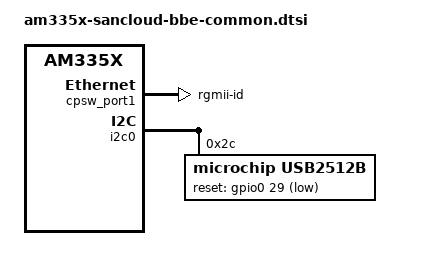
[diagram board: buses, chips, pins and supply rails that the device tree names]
// SPDX-License-Identifier: GPL-2.0-only
/*
 * Copyright (C) 2012 Texas Instruments Incorporated - https://www.ti.com/
 */

&am33xx_pinmux {
	cpsw_default: cpsw-default-pins {
		pinctrl-single,pins = <
			/* Slave 1 */
			AM33XX_PADCONF(AM335X_PIN_MII1_TX_EN, PIN_OUTPUT_PULLDOWN, MUX_MODE2)	/* mii1_txen.rgmii1_tctl */
			AM33XX_PADCONF(AM335X_PIN_MII1_RX_DV, PIN_INPUT_PULLDOWN, MUX_MODE2)	/* mii1_rxdv.rgmii1_rctl */
			AM33XX_PADCONF(AM335X_PIN_MII1_TXD3, PIN_OUTPUT_PULLDOWN, MUX_MODE2)	/* mii1_txd3.rgmii1_td3 */
			AM33XX_PADCONF(AM335X_PIN_MII1_TXD2, PIN_OUTPUT_PULLDOWN, MUX_MODE2)	/* mii1_txd2.rgmii1_td2 */
			AM33XX_PADCONF(AM335X_PIN_MII1_TXD1, PIN_OUTPUT_PULLDOWN, MUX_MODE2)	/* mii1_txd1.rgmii1_td1 */
			AM33XX_PADCONF(AM335X_PIN_MII1_TXD0, PIN_OUTPUT_PULLDOWN, MUX_MODE2)	/* mii1_txd0.rgmii1_td0 */
			AM33XX_PADCONF(AM335X_PIN_MII1_TX_CLK, PIN_OUTPUT_PULLDOWN, MUX_MODE2)	/* mii1_txclk.rgmii1_tclk */
			AM33XX_PADCONF(AM335X_PIN_MII1_RX_CLK, PIN_INPUT_PULLDOWN, MUX_MODE2)	/* mii1_rxclk.rgmii1_rclk */
			AM33XX_PADCONF(AM335X_PIN_MII1_RXD3, PIN_INPUT_PULLDOWN, MUX_MODE2)	/* mii1_rxd3.rgmii1_rd3 */
			AM33XX_PADCONF(AM335X_PIN_MII1_RXD2, PIN_INPUT_PULLDOWN, MUX_MODE2)	/* mii1_rxd2.rgmii1_rd2 */
			AM33XX_PADCONF(AM335X_PIN_MII1_RXD1, PIN_INPUT_PULLDOWN, MUX_MODE2)	/* mii1_rxd1.rgmii1_rd1 */
			AM33XX_PADCONF(AM335X_PIN_MII1_RXD0, PIN_INPUT_PULLDOWN, MUX_MODE2)	/* mii1_rxd0.rgmii1_rd0 */
		>;
	};

	cpsw_sleep: cpsw-sleep-pins {
		pinctrl-single,pins = <
			/* Slave 1 reset value */
			AM33XX_PADCONF(AM335X_PIN_MII1_TX_EN, PIN_INPUT_PULLDOWN, MUX_MODE7)
			AM33XX_PADCONF(AM335X_PIN_MII1_RX_DV, PIN_INPUT_PULLDOWN, MUX_MODE7)
			AM33XX_PADCONF(AM335X_PIN_MII1_TXD3, PIN_INPUT_PULLDOWN, MUX_MODE7)
			AM33XX_PADCONF(AM335X_PIN_MII1_TXD2, PIN_INPUT_PULLDOWN, MUX_MODE7)
			AM33XX_PADCONF(AM335X_PIN_MII1_TXD1, PIN_INPUT_PULLDOWN, MUX_MODE7)
			AM33XX_PADCONF(AM335X_PIN_MII1_TXD0, PIN_INPUT_PULLDOWN, MUX_MODE7)
			AM33XX_PADCONF(AM335X_PIN_MII1_TX_CLK, PIN_INPUT_PULLDOWN, MUX_MODE7)
			AM33XX_PADCONF(AM335X_PIN_MII1_RX_CLK, PIN_INPUT_PULLDOWN, MUX_MODE7)
			AM33XX_PADCONF(AM335X_PIN_MII1_RXD3, PIN_INPUT_PULLDOWN, MUX_MODE7)
			AM33XX_PADCONF(AM335X_PIN_MII1_RXD2, PIN_INPUT_PULLDOWN, MUX_MODE7)
			AM33XX_PADCONF(AM335X_PIN_MII1_RXD1, PIN_INPUT_PULLDOWN, MUX_MODE7)
			AM33XX_PADCONF(AM335X_PIN_MII1_RXD0, PIN_INPUT_PULLDOWN, MUX_MODE7)
		>;
	};

	usb_hub_ctrl: usb-hub-ctrl-pins {
		pinctrl-single,pins = <
			AM33XX_PADCONF(AM335X_PIN_RMII1_REF_CLK, PIN_OUTPUT_PULLUP, MUX_MODE7)     /* rmii1_refclk.gpio0_29 */
		>;
	};
};

&mac_sw {
	pinctrl-0 = <&cpsw_default>;
	pinctrl-1 = <&cpsw_sleep>;
};

&cpsw_port1 {
	phy-mode = "rgmii-id";
};

&i2c0 {
	usb2512b: usb-hub@2c {
		pinctrl-names = "default";
		pinctrl-0 = <&usb_hub_ctrl>;
		compatible = "microchip,usb2512b";
		reg = <0x2c>;
		reset-gpios = <&gpio0 29 GPIO_ACTIVE_LOW>;
	};
};
